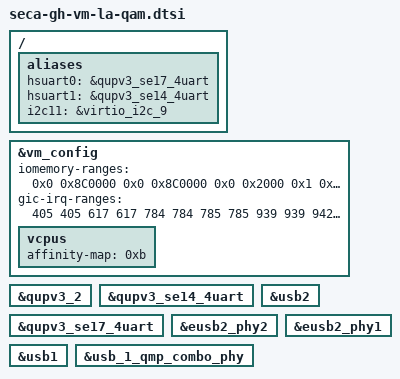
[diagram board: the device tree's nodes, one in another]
// SPDX-License-Identifier: BSD-3-Clause
/*
 * Copyright (c) Qualcomm Technologies, Inc. and/or its subsidiaries.
 */

/* Change all of these once copied this file */
#include "seca-gh-vm-la.dtsi"
#include "seca-vm-usb.dtsi"
#include "seca-gh-vm-qupv3.dtsi"
#include "seca-vm-pinctrl.dtsi"

/ {
	aliases {
		hsuart0 = &qupv3_se17_4uart;
		hsuart1 = &qupv3_se14_4uart;
		i2c11 = &virtio_i2c_9;
	};
};

&vm_config {
	iomemory-ranges = <
		/* QUPv3 Tile 2 read-only region */
		0x0 0x8C0000 0x0 0x8C0000 0x0 0x2000 0x1
		/* QUPv3 SE14 region */
		0x0 0x880000 0x0 0x880000 0x0 0x3000 0x0
		/* QUPv3 SE17 region */
		0x0 0x88C000 0x0 0x88C000 0x0 0x3000 0x0
		/* USB2 region */
		0x0 0x88e0000 0x0 0x88e0000 0x0 0x1000 0x0
		0x0 0xa200000 0x0 0xa200000 0x0 0x200000 0x0
		/* QRNG region */
		0x0 0x10cd000 0x0 0x10cd000 0x0 0x1000 0x0
		/* PDC region */
		0x0 0xb220000 0x0 0xb220000 0x0 0x10000 0x0
		/* Board serial number region */
		0x0 0x360D4000 0x0 0x360D4000 0x0 0x1000 0x1
		/* USB1 region */
		0x0 0x88eb000 0x0 0x88eb000 0x0 0x1000 0x0
		0x0 0x88e4000 0x0 0x88e4000 0x0 0x3000 0x0
		0x0 0xa400000 0x0 0xa400000 0x0 0x200000 0x0
		/* MDSS 0 region */
		0x0 0xAE00000 0x0 0xAE00000 0x0 0x180000 0x1
		/* MDSS 0 LUT DMA CTL region */
		0x0 0x0AF80000 0x0 0x0AF80000 0x0 0x1000 0x1
		/* MDSS 0 LUT DMA VQ region */
		0x0 0x0AF81000 0x0 0x0AF81000 0x0 0x10000 0x0
		/* MDSS 0 VA_TRAN CTL region */
		0x0 0xAFA4000 0x0 0xAFA4000 0x0 0x1000 0x1
		/* MDSS 0 VA_TRAN VQ region */
		0x0 0xAFA5000 0x0 0xAFA5000 0x0 0x10000 0x0
		/* MDSS 1 region */
		0x0 0x8C00000 0x0 0x8C00000 0x0 0x180000 0x1
		/* MDSS 1 LUT DMA CTL region */
		0x0 0x8D80000 0x0 0x8D80000 0x0 0x1000 0x1
		/* MDSS 1 LUT DMA VQ region */
		0x0 0x8D81000 0x0 0x8D81000 0x0 0x10000 0x0
		/* MDSS 1 VA_TRAN CTL region */
		0x0 0x8DA4000 0x0 0x8DA4000 0x0 0x1000 0x1
		/* MDSS 1 VA_TRAN VQ region */
		0x0 0x8DA5000 0x0 0x8DA5000 0x0 0x10000 0x0
		/* GPU_0_GMU region */
		0x0 0x3D40000 0x0 0x3D40000 0x0 0x1000 0x0
		/* MPROC NS1 IPCC region */
		0x0 0x9008000 0x0 0x9008000 0x0 0x1000 0x0
		/* TLMM region */
		0x0 0x0F000000 0x0 0x0F000000 0x0 0x01000000 0x0

	>;

	gic-irq-ranges = <
		/* QUPv3 SE14 GIC IRQ */
		405 405
		/* QUPv3 SE17 GIC IRQ */
		617 617
		/* USB2 IRQs */
		784 784
		785 785
		939 939
		942 942
		/* USB1 IRQs */
		789 789
		790 790
		818 818
		949 949
		950 950
		/* GPU 0 GMU */
		676 676
		/* MPROC NS1 IPCC GIC IRQ */
		471 471
	>;

	vcpus {
		affinity-map = <0xb>;
	};
};

&qupv3_2 {
	status = "ok";
};

&qupv3_se14_4uart {
	status = "ok";
};

&qupv3_se17_4uart {
	status = "ok";
};

&usb2 {
	status = "ok";
};

&eusb2_phy2 {
	status = "ok";
};

&eusb2_phy1 {
	status = "ok";
};

&usb1 {
	status = "ok";
};

&usb_1_qmp_combo_phy {
	status = "ok";
};
